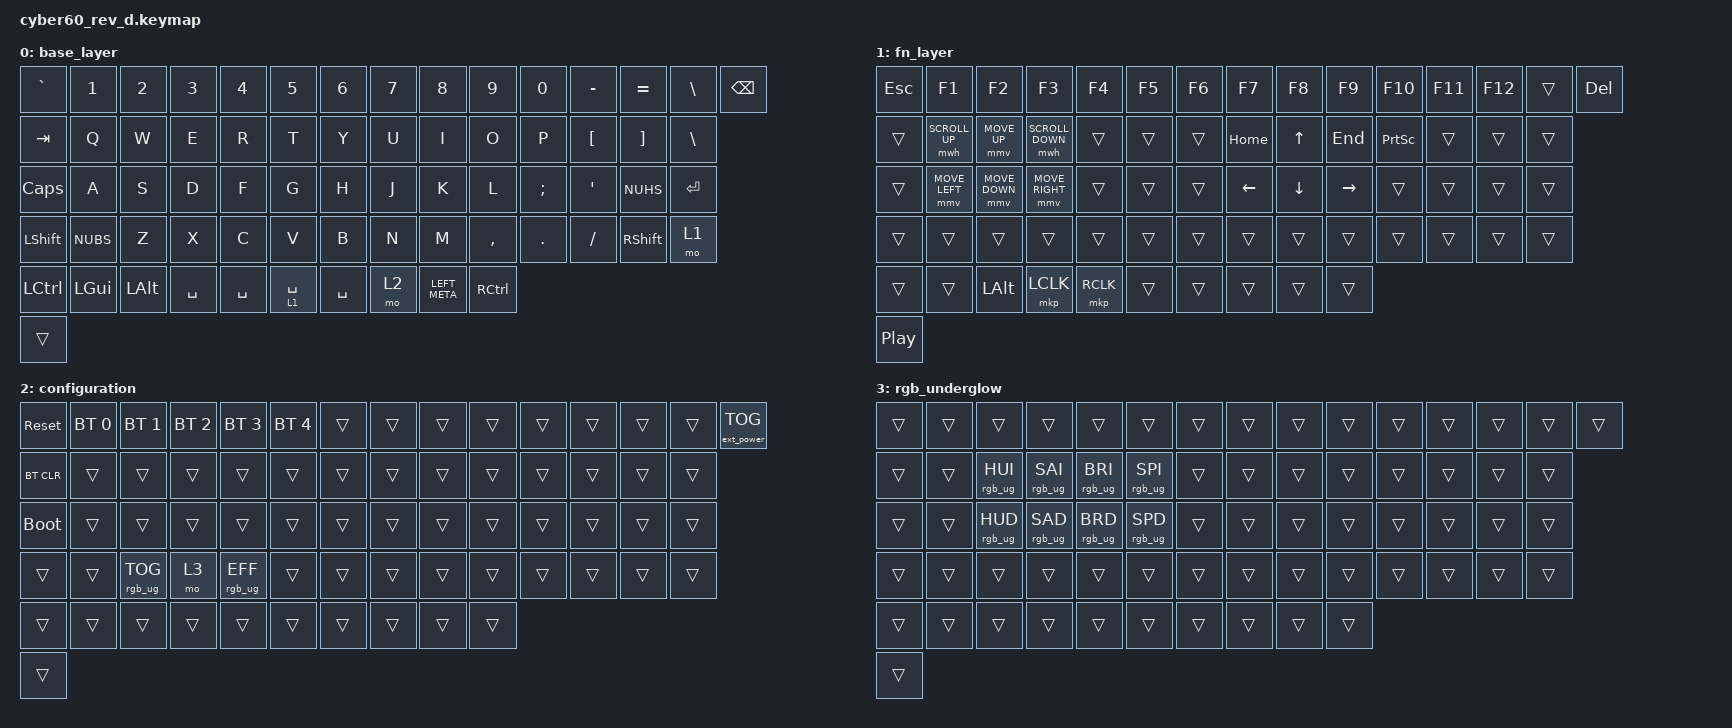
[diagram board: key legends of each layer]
#include <behaviors.dtsi>
#include <dt-bindings/zmk/mouse.h>
#include <dt-bindings/zmk/bt.h>
#include <dt-bindings/zmk/ext_power.h>
#include <dt-bindings/zmk/keys.h>
#include <dt-bindings/zmk/rgb.h>

#define FN1 1

&mmv {
    acceleration-exponent = <1>;
    time-to-max-speed-ms = <800>;
    delay-ms = <0>;
};

&mwh {
    acceleration-exponent = <2>;      // 0
    time-to-max-speed-ms = <20>;    // 40
    delay-ms = <0>;                   // 10
};

#define U_MOUSE_MOVE_MAX 2250       // 600
#define U_MOUSE_SCROLL_MAX 10      // 10

#undef MOVE_UP
#undef MOVE_DOWN
#undef MOVE_LEFT
#undef MOVE_RIGHT

#define MOVE_UP MOVE_VERT(-U_MOUSE_MOVE_MAX)
#define MOVE_DOWN MOVE_VERT(U_MOUSE_MOVE_MAX)
#define MOVE_LEFT MOVE_HOR(-U_MOUSE_MOVE_MAX)
#define MOVE_RIGHT MOVE_HOR(U_MOUSE_MOVE_MAX)

#undef SCROLL_UP
#undef SCROLL_DOWN
#undef SCROLL_LEFT
#undef SCROLL_RIGHT

#define SCROLL_UP SCROLL_VERT(U_MOUSE_SCROLL_MAX)
#define SCROLL_DOWN SCROLL_VERT(-U_MOUSE_SCROLL_MAX)
#define SCROLL_LEFT SCROLL_HOR(-U_MOUSE_SCROLL_MAX)
#define SCROLL_RIGHT SCROLL_HOR(U_MOUSE_SCROLL_MAX)

/ {
    combos {
        compatible = "zmk,combos";

        Escape {
            bindings = <&kp ESCAPE>;
            key-positions = <0 1>;
        };

        Middle-click {
            bindings = <&mkp MB3>;
            key-positions = <60 61>;
        };
    };

    keymap {
        compatible = "zmk,keymap";

        base_layer {
            // Base layer
            // ------------------------------------------------------------------------------------------
            // | ESC |  1  |  2  |  3  |  4  |  5  |  6  |  7  |  8  |  9  |  0  |  -  |  =  |   BKSP   |
            // |  TAB |  Q  |  W  |  E  |  R  |  T  |  Y  |  U  |  I  |  O  |  P  |  [  |  ]  |   "|"   |
            // | CAPS  |  A  |  S  |  D  |  F  |  G  |  H  |  J  |  K  |  L  |  ;  |  '  |NUHS| ENTER   |
            // | SHIFT |NUBS| Z |  X  |  C  |  V  |  B  |  N  |  M  |  ,  |  .  |  /  |    Shift   | FN |
            // |  LCTL  |  LWIN  |  LALT  | SPACE  | SPACE |    SPACE   |  RALT | FN  |   RWIN  | RCTRL |
            // | Rotary | (<-- Rotary switch) ----------------------------------------------------------- 

            bindings = <
&kp GRAVE  &kp N1    &kp N2    &kp N3     &kp N4     &kp N5       &kp N6     &kp N7  &kp N8         &kp N9     &kp N0    &kp MINUS  &kp EQUAL  &kp BSLH  &kp BSPC
&kp TAB    &kp Q     &kp W     &kp E      &kp R      &kp T        &kp Y      &kp U   &kp I          &kp O      &kp P     &kp LBKT   &kp RBKT   &kp BSLH
&kp CLCK   &kp A     &kp S     &kp D      &kp F      &kp G        &kp H      &kp J   &kp K          &kp L      &kp SEMI  &kp SQT    &kp NUHS   &kp RET
&kp LSHFT  &kp NUBS  &kp Z     &kp X      &kp C      &kp V        &kp B      &kp N   &kp M          &kp COMMA  &kp DOT   &kp FSLH   &kp RSHFT  &mo 1
&kp LCTRL  &kp LGUI  &kp LALT  &kp SPACE  &kp SPACE  &lt 1 SPACE  &kp SPACE  &mo 2   &kp LEFT_META  &kp RCTRL
&trans
            >;
        };

        fn_layer {
            // Function layer
            // ------------------------------------------------------------------------------------------
            // | RESET | F1 |  F2 |  F3 |  F4 |  F5 |  F6 |  F7 |  F8 |  F9 | F10 | F11 | F12 |TRNS | DEL |
            // |BT_CLR |TRNS | UP  | BT0 | BT1 | BT2 | BT3 | BT4 | TRNS | TRNS | TRNS | TRNS | TRNS | TRNS|
            // | BOOTL  |LEFT |DOWN |RIGHT|TRNS |TRNS |TRNS | TRNS| TRNS |TRNS| TRNS |TRNS | TRNS | TRNS  |
            // | TRNS |TRNS|TRNS|TRNS|TRNS | TRNS| TRNS | TRNS |  TRNS| TRNS | TRNS| TRNS |   TRNS   |TRNS|
            // |  TRNS | TRNS | TRNS |      TRNS      | TRNS |     TRNS     |  TRNS |  TRNS | TRNS | TRNS |
            // | Rotary | (<-- Rotary switch) ----------------------------------------------------------- 

            bindings = <
&kp ESCAPE  &kp F1          &kp F2          &kp F3            &kp F4     &kp F5  &kp F6  &kp F7    &kp F8    &kp F9     &kp F10          &kp F11  &kp F12  &trans  &kp DEL
&trans      &mwh SCROLL_UP  &mmv MOVE_UP    &mwh SCROLL_DOWN  &trans     &trans  &trans  &kp HOME  &kp UP    &kp END    &kp PRINTSCREEN  &trans   &trans   &trans
&trans      &mmv MOVE_LEFT  &mmv MOVE_DOWN  &mmv MOVE_RIGHT   &trans     &trans  &trans  &kp LEFT  &kp DOWN  &kp RIGHT  &trans           &trans   &trans   &trans
&trans      &trans          &trans          &trans            &trans     &trans  &trans  &trans    &trans    &trans     &trans           &trans   &trans   &trans
&trans      &trans          &kp LEFT_ALT    &mkp LCLK         &mkp RCLK  &trans  &trans  &trans    &trans    &trans
&kp C_PP
            >;
        };

        configuration {
            bindings = <
&sys_reset   &bt BT_SEL 0  &bt BT_SEL 1     &bt BT_SEL 2  &bt BT_SEL 3     &bt BT_SEL 4  &trans  &trans  &trans  &trans  &trans  &trans  &trans  &trans  &ext_power EP_TOG
&bt BT_CLR   &trans        &trans           &trans        &trans           &trans        &trans  &trans  &trans  &trans  &trans  &trans  &trans  &trans
&bootloader  &trans        &trans           &trans        &trans           &trans        &trans  &trans  &trans  &trans  &trans  &trans  &trans  &trans
&trans       &trans        &rgb_ug RGB_TOG  &mo 3         &rgb_ug RGB_EFF  &trans        &trans  &trans  &trans  &trans  &trans  &trans  &trans  &trans
&trans       &trans        &trans           &trans        &trans           &trans        &trans  &trans  &trans  &trans
&trans
            >;
        };

        rgb_underglow {
            bindings = <
&trans  &trans  &trans           &trans           &trans           &trans           &trans  &trans  &trans  &trans  &trans  &trans  &trans  &trans  &trans
&trans  &trans  &rgb_ug RGB_HUI  &rgb_ug RGB_SAI  &rgb_ug RGB_BRI  &rgb_ug RGB_SPI  &trans  &trans  &trans  &trans  &trans  &trans  &trans  &trans
&trans  &trans  &rgb_ug RGB_HUD  &rgb_ug RGB_SAD  &rgb_ug RGB_BRD  &rgb_ug RGB_SPD  &trans  &trans  &trans  &trans  &trans  &trans  &trans  &trans
&trans  &trans  &trans           &trans           &trans           &trans           &trans  &trans  &trans  &trans  &trans  &trans  &trans  &trans
&trans  &trans  &trans           &trans           &trans           &trans           &trans  &trans  &trans  &trans
&trans
            >;
        };
    };
};
